# STM32N645 register map
File version: 1.0
CPU: CM55 r0p1, little endian, no MPU, FPU, vendor SysTick, 8 interrupt priority bits
Registers are 32-bit, read-write, reset 0x0 unless marked. A register's access mark holds for its fields unless they carry their own. Offsets are from the block's base; [hi:lo] are bit positions; {n}, {i} and the like mark numbered series; 'fields as' and 'values as' point back to an identical list.

## ICACHE — Texture cache
Base 0x48035000
Same registers: ICACHE_S 0x58035000
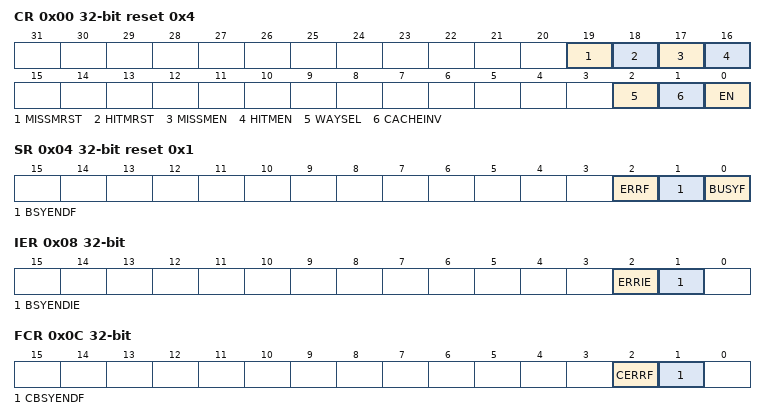
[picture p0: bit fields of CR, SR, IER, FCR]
0x00 CR access per field reset 0x4 — ICACHE control register
  [19] MISSMRST rw — miss monitor reset
  [18] HITMRST rw — hit monitor reset
  [17] MISSMEN rw — miss monitor enable
  [16] HITMEN rw — hit monitor enable
  [2] WAYSEL rw — cache associativity mode selection
  [1] CACHEINV wo — cache invalidation
  [0] EN rw — enable
0x04 SR ro reset 0x1 — ICACHE status register
  [2] ERRF — cache error flag
  [1] BSYENDF — busy end flag
  [0] BUSYF — busy flag
0x08 IER — ICACHE interrupt enable register
  [2] ERRIE — interrupt enable on cache error
  [1] BSYENDIE — interrupt enable on busy end
0x0C FCR wo — ICACHE flag clear register
  [2] CERRF — clear cache error flag
  [1] CBSYENDF — clear busy end flag
0x10 HMONR ro — ICACHE hit monitor register
  [31:0] HITMON — cache hit monitor counter
0x14 MMONR ro — ICACHE miss monitor register
  [15:0] MISSMON — cache miss monitor counter

## IWDG — Independent watchdog
Base 0x46004800
Same registers: IWDG_S 0x56004800
0x00 KR wo — IWDG key register
  [15:0] KEY — Key value (write only, read 0x0000)
0x04 PR — IWDG prescaler register
  [3:0] PR — Prescaler divider
0x08 RLR reset 0xFFF — IWDG reload register
  [11:0] RL — Watchdog counter reload value
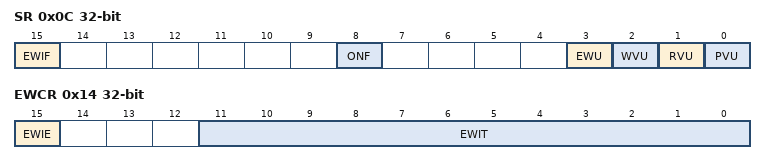
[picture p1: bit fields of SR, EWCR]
0x0C SR ro — IWDG status register
  [15] EWIF — Watchdog early interrupt flag
  [8] ONF — Watchdog enable status bit
  [3] EWU — Watchdog interrupt comparator value update
  [2] WVU — Watchdog counter window value update
  [1] RVU — Watchdog counter reload value update
  [0] PVU — Watchdog prescaler value update
0x10 WINR reset 0xFFF — IWDG window register
  [11:0] WIN — Watchdog counter window value
0x14 EWCR — IWDG early wake-up interrupt register
  [15] EWIE — Watchdog early interrupt enable
  [11:0] EWIT — Watchdog counter window value
0x18 ICR — IWDG interrupt clear register
  [15] EWIC — Watchdog early interrupt acknowledge

## MDIOS — Management data input/output
Base 0x40009400
Same registers: MDIOS_S 0x50009400
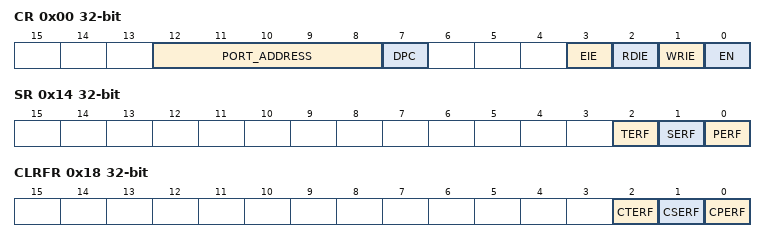
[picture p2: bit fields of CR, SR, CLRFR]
0x00 CR — MDIOS configuration register
  [12:8] PORT_ADDRESS — slave address
  [7] DPC — disable preamble check
  [3] EIE — error interrupt enable
  [2] RDIE — register read interrupt enable
  [1] WRIE — register write interrupt enable
  [0] EN — peripheral enable
0x04 WRFR ro — MDIOS write flag register
  [31:0] WRF — write flags for MDIOS registers 0 to 31.
0x08 CWRFR — MDIOS clear write flag register
  [31:0] CWRF — clear the write flag
0x0C RDFR ro — MDIOS read flag register
  [31:0] RDF — read flags for MDIOS registers 0 to 31.
0x10 CRDFR — MDIOS clear read flag register
  [31:0] CRDF — clear the read flag
0x14 SR ro — MDIOS status register
  [2] TERF — turnaround error flag
  [1] SERF — start error flag
  [0] PERF — preamble error flag
0x18 CLRFR — MDIOS clear flag register
  [2] CTERF — clear the turnaround error flag
  [1] CSERF — clear the start error flag
  [0] CPERF — clear the preamble error flag
{0x100+4i} DINR{i} ro (i=0..31) — MDIOS input data register {i}
  [15:0] DIN — input data received from MDIO master during write frames
{0x180+4i} DOUTR{i} (i=0..31) — MDIOS output data register {i}
  [15:0] DOUT — output data sent to MDIO Master during read frames

## RISAF — Resource isolation slave unit for address space protection
Base 0x44026000
Same registers: RISAF_S 0x54026000
0x00 CR — RISAF configuration register
  [0] GLOCK — global lock
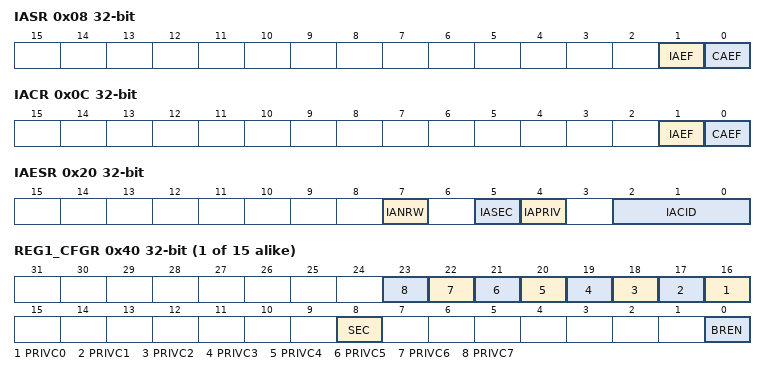
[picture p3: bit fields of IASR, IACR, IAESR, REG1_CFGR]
0x08 IASR ro — RISAF illegal access status register
  [1] IAEF — illegal access error flag
  [0] CAEF — configuration access error flag
0x0C IACR wo — RISAF illegal access clear register
  fields as IASR
0x20 IAESR ro — RISAF illegal access error status register
  [7] IANRW — illegal access read/write
  [5] IASEC — illegal access security
  [4] IAPRIV — illegal access privileged
  [2:0] IACID — illegal access compartment ID
0x24 IADDR ro — RISAF illegal address register
  [31:0] IADD — illegal address
{0x0+0x40*i} REG{i}_CFGR (i=1..15) — RISAF region {i} configuration register
  [n+16] PRIVC{n} (n=0..7) — privileged access for compartment y
  [8] SEC — secure region
  [0] BREN — base region enable
{0x4+0x40*i} REG{i}_STARTR (i=1..15) — RISAF region {i} start-address register
  [31:0] BADDSTART — Base region address start
{0x8+0x40*i} REG{i}_ENDR reset 0xFFF (i=1..15) — RISAF region {i} end-address register
  [31:0] BADDEND — Base region address end
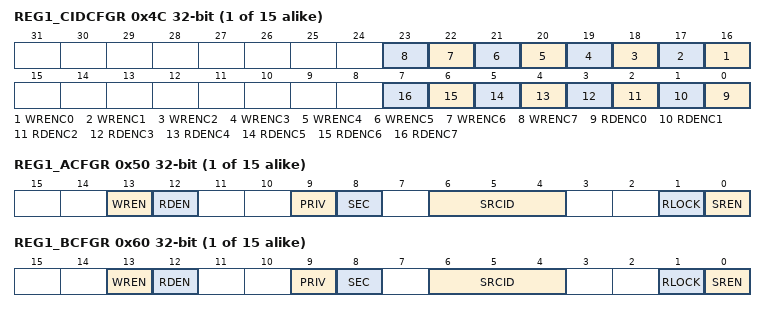
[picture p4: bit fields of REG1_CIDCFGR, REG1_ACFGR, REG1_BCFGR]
{0xC+0x40*i} REG{i}_CIDCFGR (i=1..15) — RISAF region {i} CID configuration register
  [n+16] WRENC{n} (n=0..7) — write enable for compartment y
  [n] RDENC{n} (n=0..7) — read enable for compartment y
{0x10+0x40*i} REG{i}_ACFGR (i=1..15) — RISAF region {i} subregion A configuration register
  [13] WREN — write enable
  [12] RDEN — read enable
  [9] PRIV — privileged subregion
  [8] SEC — secure subregion
  [6:4] SRCID — subregion CID
  [1] RLOCK — resource lock
  [0] SREN — subregion enable
{0x14+0x40*i} REG{i}_ASTARTR (i=1..15) — RISAF region {i} subregion A start-address register
  [31:0] SADDSTART — subregion address start
{0x18+0x40*i} REG{i}_AENDR reset 0xFFF (i=1..15) — RISAF region {i} subregion A end-address register
  [31:0] SADDEND — subregion address end
{0x1C+0x40*i} REG{i}_ANESTR (i=1..15) — RISAF region {i} subregion A nested mode register
  [2] DCEN — delegated configuration enable
{0x20+0x40*i} REG{i}_BCFGR (i=1..15) — RISAF region {i} subregion B configuration register
  fields as REG1_ACFGR
{0x24+0x40*i} REG{i}_BSTARTR (i=1..15) — RISAF region {i} subregion B start-address register
  [31:0] SADDSTART — subregion address start
{0x28+0x40*i} REG{i}_BENDR reset 0xFFF (i=1..15) — RISAF region {i} subregion B end-address register
  [31:0] SADDEND — subregion address end
{0x2C+0x40*i} REG{i}_BNESTR (i=1..15) — RISAF region {i} subregion B nested mode register
  [2] DCEN — delegated configuration enable
